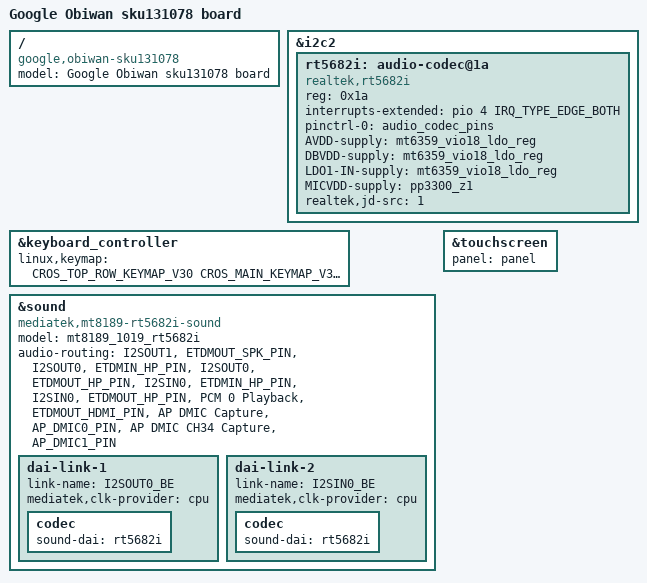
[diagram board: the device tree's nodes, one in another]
// SPDX-License-Identifier: (GPL-2.0 OR MIT)
/*
 * Copyright (C) 2025 Google Inc.
 */
/dts-v1/;
#include "mt8189-skywalker-obiwan.dtsi"

/ {
	model = "Google Obiwan sku131078 board";
	compatible = "google,obiwan-sku131078", "google,obiwan",
		     "mediatek,mt8189";
};

&i2c2 {
	/delete-node/ audio-codec@1a;

	rt5682i: audio-codec@1a {
		compatible = "realtek,rt5682i";
		reg = <0x1a>;
		interrupts-extended = <&pio 4 IRQ_TYPE_EDGE_BOTH>;
		pinctrl-names = "default";
		pinctrl-0 = <&audio_codec_pins>;
		#sound-dai-cells = <0>;

		AVDD-supply = <&mt6359_vio18_ldo_reg>;
		DBVDD-supply = <&mt6359_vio18_ldo_reg>;
		LDO1-IN-supply = <&mt6359_vio18_ldo_reg>;
		MICVDD-supply = <&pp3300_z1>;
		realtek,jd-src = <1>;
		status = "okay";
	};
};

&keyboard_controller {
	linux,keymap = <
		CROS_TOP_ROW_KEYMAP_V30
		CROS_MAIN_KEYMAP_V30

		MATRIX_KEY(0x00, 0x02, KEY_BACK)		/* T1 */
		MATRIX_KEY(0x03, 0x02, KEY_REFRESH)		/* T2 */
		MATRIX_KEY(0x02, 0x02, KEY_ZOOM)		/* T3 */
		MATRIX_KEY(0x01, 0x02, KEY_SCALE)		/* T4 */
		MATRIX_KEY(0x04, 0x04, KEY_SYSRQ)		/* T5 */
		MATRIX_KEY(0x02, 0x04, KEY_BRIGHTNESSDOWN)	/* T6 */
		MATRIX_KEY(0x01, 0x04, KEY_BRIGHTNESSUP)	/* T7 */
		MATRIX_KEY(0x02, 0x0b, KEY_PLAYPAUSE)		/* T8 */
		MATRIX_KEY(0x01, 0x09, KEY_MICMUTE)		/* T9 */
		MATRIX_KEY(0x00, 0x04, KEY_MUTE)		/* T10 */
		MATRIX_KEY(0x00, 0x01, KEY_VOLUMEDOWN)		/* T11 */
		MATRIX_KEY(0x01, 0x05, KEY_VOLUMEUP)		/* T12 */
		MATRIX_KEY(0x03, 0x05, KEY_ACCESSIBILITY)	/* T13 */
		MATRIX_KEY(0x00, 0x0b, KEY_DICTATE)		/* T14 */
	>;
};

&sound {
	compatible = "mediatek,mt8189-rt5682i-sound";
	model = "mt8189_1019_rt5682i";
	status = "okay";

	audio-routing = "I2SOUT1", "ETDMOUT_SPK_PIN",
			"I2SOUT0", "ETDMIN_HP_PIN",
			"I2SOUT0", "ETDMOUT_HP_PIN",
			"I2SIN0", "ETDMIN_HP_PIN",
			"I2SIN0", "ETDMOUT_HP_PIN",
			"PCM 0 Playback", "ETDMOUT_HDMI_PIN",
			"AP DMIC Capture", "AP_DMIC0_PIN",
			"AP DMIC CH34 Capture", "AP_DMIC1_PIN";

	dai-link-1 {
		link-name = "I2SOUT0_BE";
		mediatek,clk-provider = "cpu";

		codec {
			sound-dai = <&rt5682i>;
		};
	};

	dai-link-2 {
		link-name = "I2SIN0_BE";
		mediatek,clk-provider = "cpu";

		codec {
			sound-dai = <&rt5682i>;
		};
	};
};

&touchscreen {
       panel = <&panel>;
};
